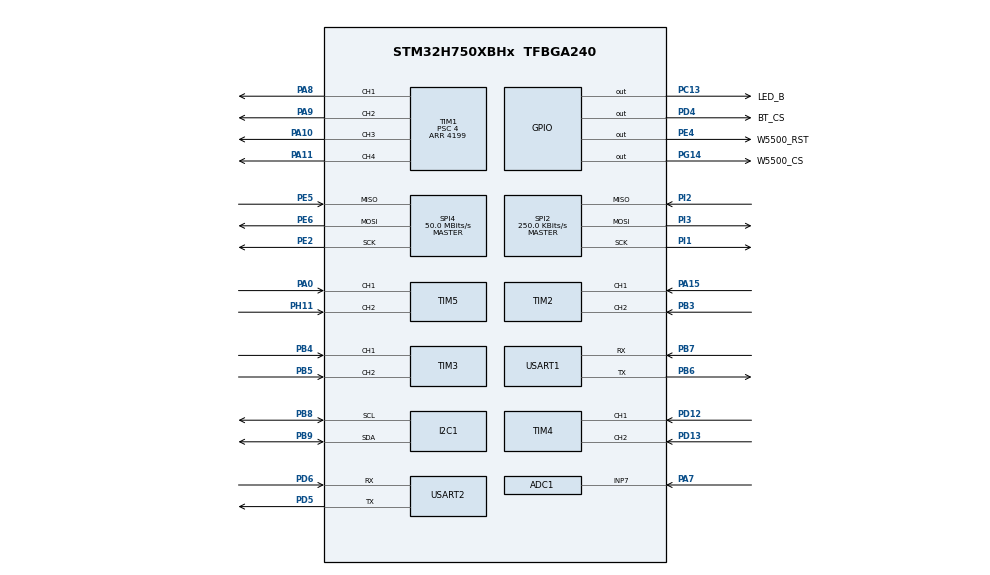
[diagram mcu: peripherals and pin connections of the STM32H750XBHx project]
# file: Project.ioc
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ADC1.Channel-0\#ChannelRegularConversion=ADC_CHANNEL_7
ADC1.NbrOfConversionFlag=1
ADC1.OffsetNumber-0\#ChannelRegularConversion=ADC_OFFSET_NONE
ADC1.OffsetSignedSaturation-0\#ChannelRegularConversion=DISABLE
ADC1.Rank-0\#ChannelRegularConversion=1
ADC1.SamplingTime-0\#ChannelRegularConversion=ADC_SAMPLETIME_1CYCLE_5
ADC1.master=1
CORTEX_M7.AccessPermission-Cortex_Memory_Protection_Unit_Region0_Settings=MPU_REGION_FULL_ACCESS
CORTEX_M7.AccessPermission-Cortex_Memory_Protection_Unit_Region1_Settings=MPU_REGION_FULL_ACCESS
CORTEX_M7.AccessPermission-Cortex_Memory_Protection_Unit_Region2_Settings=MPU_REGION_FULL_ACCESS
CORTEX_M7.AccessPermission-Cortex_Memory_Protection_Unit_Region3_Settings=MPU_REGION_FULL_ACCESS
CORTEX_M7.BaseAddress-Cortex_Memory_Protection_Unit_Region0_Settings=0x30000000
CORTEX_M7.BaseAddress-Cortex_Memory_Protection_Unit_Region1_Settings=0x40081000
CORTEX_M7.BaseAddress-Cortex_Memory_Protection_Unit_Region2_Settings=0x58020000
CORTEX_M7.BaseAddress-Cortex_Memory_Protection_Unit_Region3_Settings=0x40000000
CORTEX_M7.CPU_DCache=Enabled
CORTEX_M7.CPU_ICache=Enabled
CORTEX_M7.DisableExec-Cortex_Memory_Protection_Unit_Region0_Settings=MPU_INSTRUCTION_ACCESS_ENABLE
CORTEX_M7.DisableExec-Cortex_Memory_Protection_Unit_Region1_Settings=MPU_INSTRUCTION_ACCESS_ENABLE
CORTEX_M7.DisableExec-Cortex_Memory_Protection_Unit_Region2_Settings=MPU_INSTRUCTION_ACCESS_ENABLE
CORTEX_M7.DisableExec-Cortex_Memory_Protection_Unit_Region3_Settings=MPU_INSTRUCTION_ACCESS_ENABLE
CORTEX_M7.Enable-Cortex_Memory_Protection_Unit_Region0_Settings=MPU_REGION_ENABLE
CORTEX_M7.Enable-Cortex_Memory_Protection_Unit_Region1_Settings=MPU_REGION_ENABLE
CORTEX_M7.Enable-Cortex_Memory_Protection_Unit_Region2_Settings=MPU_REGION_ENABLE
CORTEX_M7.Enable-Cortex_Memory_Protection_Unit_Region3_Settings=MPU_REGION_ENABLE
CORTEX_M7.Enable-Cortex_Memory_Protection_Unit_Region4_Settings=__NULL
CORTEX_M7.IsBufferable-Cortex_Memory_Protection_Unit_Region0_Settings=MPU_ACCESS_NOT_BUFFERABLE
CORTEX_M7.MPU_Control=MPU_PRIVILEGED_DEFAULT
CORTEX_M7.Size-Cortex_Memory_Protection_Unit_Region0_Settings=MPU_REGION_SIZE_256KB
CORTEX_M7.Size-Cortex_Memory_Protection_Unit_Region1_Settings=MPU_REGION_SIZE_256KB
CORTEX_M7.Size-Cortex_Memory_Protection_Unit_Region2_Settings=MPU_REGION_SIZE_16KB
CORTEX_M7.Size-Cortex_Memory_Protection_Unit_Region3_Settings=MPU_REGION_SIZE_1MB
I2C1.Timing=0x10C0ECFF
Mcu.Family=STM32H7
Mcu.Name=STM32H750XBHx
Mcu.Package=TFBGA240
NVIC.PriorityGroup=NVIC_PRIORITYGROUP_4
NVIC.TIM6_DAC_IRQn=true\:15\:0\:false\:false\:true\:false\:true\:true
NVIC.TimeBase=TIM6_DAC_IRQn
NVIC.TimeBaseIP=TIM6
PA0.Signal=S_TIM5_CH1
PA10.Signal=S_TIM1_CH3
PA11.Signal=S_TIM1_CH4
PA15\ (JTDI).Signal=S_TIM2_CH1_ETR
PA7.Signal=ADCx_INP7
PA8.Signal=S_TIM1_CH1
PA9.Signal=S_TIM1_CH2
PB3\ (JTDO/TRACESWO).Signal=S_TIM2_CH2
PB4\ (NJTRST).Signal=S_TIM3_CH1
PB5.Signal=S_TIM3_CH2
PB6.Mode=Asynchronous
PB6.Signal=USART1_TX
PB7.Mode=Asynchronous
PB7.Signal=USART1_RX
PB8.Mode=I2C
PB8.Signal=I2C1_SCL
PB9.Mode=I2C
PB9.Signal=I2C1_SDA
PC13.GPIO_Label=LED_B
PC13.Signal=GPIO_Output
PD12.Signal=S_TIM4_CH1
PD13.Signal=S_TIM4_CH2
PD4.GPIO_Label=BT_CS
PD4.Signal=GPIO_Output
PD5.Mode=Asynchronous
PD5.Signal=USART2_TX
PD6.Mode=Asynchronous
PD6.Signal=USART2_RX
PE2.Mode=Full_Duplex_Master
PE2.Signal=SPI4_SCK
PE4.GPIO_Label=W5500_RST
PE4.Signal=GPIO_Output
PE5.Mode=Full_Duplex_Master
PE5.Signal=SPI4_MISO
PE6.Mode=Full_Duplex_Master
PE6.Signal=SPI4_MOSI
PG14.GPIO_Label=W5500_CS
PG14.Signal=GPIO_Output
PH0-OSC_IN\ (PH0).Mode=HSE-External-Oscillator
PH0-OSC_IN\ (PH0).Signal=RCC_OSC_IN
PH1-OSC_OUT\ (PH1).Mode=HSE-External-Oscillator
PH1-OSC_OUT\ (PH1).Signal=RCC_OSC_OUT
PH11.Signal=S_TIM5_CH2
PI1.Mode=Full_Duplex_Master
PI1.Signal=SPI2_SCK
PI2.Mode=Full_Duplex_Master
PI2.Signal=SPI2_MISO
PI3.Mode=Full_Duplex_Master
PI3.Signal=SPI2_MOSI
ProjectManager.HeapSize=0x1000
ProjectManager.StackSize=0x1000
ProjectManager.TargetToolchain=MDK-ARM V5.27
RCC.ADCCLockSelection=RCC_ADCCLKSOURCE_CLKP
RCC.ADCFreq_Value=64000000
RCC.APB1Freq_Value=100000000
RCC.APB2Freq_Value=100000000
RCC.APB3Freq_Value=100000000
RCC.APB4Freq_Value=100000000
RCC.CortexFreq_Value=400000000
RCC.D1PPRE=RCC_APB3_DIV2
RCC.D2PPRE1=RCC_APB1_DIV2
RCC.D2PPRE2=RCC_APB2_DIV2
RCC.D3PPRE=RCC_APB4_DIV2
RCC.DIVM1=5
RCC.DIVM2=5
RCC.DIVM3=5
RCC.DIVN1=160
RCC.DIVN2=192
RCC.DIVN3=192
RCC.HCLKFreq_Value=200000000
RCC.HPRE=RCC_HCLK_DIV2
RCC.PLLSourceVirtual=RCC_PLLSOURCE_HSE
RCC.SPI123CLockSelection=RCC_SPI123CLKSOURCE_CLKP
RCC.SYSCLKFreq_VALUE=400000000
RCC.SYSCLKSource=RCC_SYSCLKSOURCE_PLLCLK
RCC.Tim1Mul=2
RCC.USBFreq_Value=400000000
SH.ADCx_INP7.0=ADC1_INP7,IN7-Single-Ended
SH.S_TIM1_CH1.0=TIM1_CH1,PWM Generation1 CH1
SH.S_TIM1_CH2.0=TIM1_CH2,PWM Generation2 CH2
SH.S_TIM1_CH3.0=TIM1_CH3,PWM Generation3 CH3
SH.S_TIM1_CH4.0=TIM1_CH4,PWM Generation4 CH4
SH.S_TIM2_CH1_ETR.0=TIM2_CH1,Encoder_Interface
SH.S_TIM2_CH2.0=TIM2_CH2,Encoder_Interface
SH.S_TIM3_CH1.0=TIM3_CH1,Encoder_Interface
SH.S_TIM3_CH2.0=TIM3_CH2,Encoder_Interface
SH.S_TIM4_CH1.0=TIM4_CH1,Encoder_Interface
SH.S_TIM4_CH2.0=TIM4_CH2,Encoder_Interface
SH.S_TIM5_CH1.0=TIM5_CH1,Encoder_Interface
SH.S_TIM5_CH2.0=TIM5_CH2,Encoder_Interface
SPI2.BaudRatePrescaler=SPI_BAUDRATEPRESCALER_256
SPI2.CLKPhase=SPI_PHASE_2EDGE
SPI2.CLKPolarity=SPI_POLARITY_HIGH
SPI2.CalculateBaudRate=250.0 KBits/s
SPI2.DataSize=SPI_DATASIZE_8BIT
SPI2.Direction=SPI_DIRECTION_2LINES
SPI2.FirstBit=SPI_FIRSTBIT_LSB
SPI2.Mode=SPI_MODE_MASTER
SPI2.NSSPMode=SPI_NSS_PULSE_DISABLE
SPI2.VirtualType=VM_MASTER
SPI4.CalculateBaudRate=50.0 MBits/s
SPI4.DataSize=SPI_DATASIZE_8BIT
SPI4.Direction=SPI_DIRECTION_2LINES
SPI4.Mode=SPI_MODE_MASTER
SPI4.NSSPMode=SPI_NSS_PULSE_DISABLE
SPI4.VirtualType=VM_MASTER
TIM1.Channel-PWM\ Generation1\ CH1=TIM_CHANNEL_1
TIM1.Channel-PWM\ Generation2\ CH2=TIM_CHANNEL_2
TIM1.Channel-PWM\ Generation3\ CH3=TIM_CHANNEL_3
TIM1.Channel-PWM\ Generation4\ CH4=TIM_CHANNEL_4
TIM1.Period=4199
TIM1.Prescaler=4
USART1.VirtualMode-Asynchronous=VM_ASYNC
USART2.VirtualMode-Asynchronous=VM_ASYNC
VP_MEMORYMAP_VS_MEMORYMAP.Mode=CurAppReg
VP_SYS_VS_tim6.Mode=TIM6
VP_TIM1_VS_ClockSourceINT.Mode=Internal
board=custom

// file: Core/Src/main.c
/* USER CODE BEGIN Header */
/**
  ******************************************************************************
  * @file           : main.c
  * @brief          : Main program body
  ******************************************************************************
  * @attention
  *
  * <h2><center>&copy; Copyright (c) 2021 STMicroelectronics.
  * All rights reserved.</center></h2>
  *
  * This software component is licensed by ST under Ultimate Liberty license
  * SLA0044, the "License"; You may not use this file except in compliance with
  * the License. You may obtain a copy of the License at:
  *                             www.st.com/SLA0044
  *
  ******************************************************************************
  */
/* USER CODE END Header */
#include "main.h"
#include "adc.h"
#include "i2c.h"
#include "memorymap.h"
#include "spi.h"
#include "tim.h"
#include "usart.h"
#include "gpio.h"

/* USER CODE BEGIN Includes */
#include <stdio.h>
#include "adc.h"
#include "lcd_spi_200.h"
#include "servo.h"
#include "robot.h"

extern void freertos_start(void);

/* USER CODE END Includes */

void SystemClock_Config(void);
void PeriphCommonClock_Config(void);
static void MPU_Config(void);

int main(void)
{

  /* MPU Configuration--------------------------------------------------------*/
  MPU_Config();

  /* Enable the CPU Cache */

  /* Enable I-Cache---------------------------------------------------------*/
  SCB_EnableICache();

  /* Enable D-Cache---------------------------------------------------------*/
  SCB_EnableDCache();

  /* MCU Configuration--------------------------------------------------------*/

  /* Reset of all peripherals, Initializes the Flash interface and the Systick. */
  HAL_Init();

  /* Configure the system clock */
  SystemClock_Config();

  /* Configure the peripherals common clocks */
  PeriphCommonClock_Config();

  /* Initialize all configured peripherals */
  MX_GPIO_Init();
  MX_USART1_UART_Init();
  MX_SPI4_Init();
  MX_SPI2_Init();
  MX_TIM1_Init();
  MX_TIM2_Init();
  MX_TIM3_Init();
  MX_TIM4_Init();
  MX_TIM5_Init();
  MX_USART2_UART_Init();
  MX_I2C1_Init();
  MX_ADC1_Init();
  /* USER CODE BEGIN 2 */
  MX_GPIO_UserInit();
  SPI_LCD_Init();
  Servo_Init();
  Robot_Init();
  /* FreeRTOS 调度器（不再返回） */
    freertos_start();
  /* USER CODE END 2 */

  /* Infinite loop */
  while (1)
  {

  }
}

void SystemClock_Config(void)
{
  RCC_OscInitTypeDef RCC_OscInitStruct = {0};
  RCC_ClkInitTypeDef RCC_ClkInitStruct = {0};

  /** Supply configuration update enable
  */
  HAL_PWREx_ConfigSupply(PWR_LDO_SUPPLY);

  /** Configure the main internal regulator output voltage
  */
  __HAL_PWR_VOLTAGESCALING_CONFIG(PWR_REGULATOR_VOLTAGE_SCALE1);

  while(!__HAL_PWR_GET_FLAG(PWR_FLAG_VOSRDY)) {}

  /** Initializes the RCC Oscillators according to the specified parameters
  * in the RCC_OscInitTypeDef structure.
  */
  RCC_OscInitStruct.OscillatorType = RCC_OSCILLATORTYPE_HSI|RCC_OSCILLATORTYPE_HSE;
  RCC_OscInitStruct.HSEState = RCC_HSE_ON;
  RCC_OscInitStruct.HSIState = RCC_HSI_DIV1;
  RCC_OscInitStruct.HSICalibrationValue = RCC_HSICALIBRATION_DEFAULT;
  RCC_OscInitStruct.PLL.PLLState = RCC_PLL_ON;
  RCC_OscInitStruct.PLL.PLLSource = RCC_PLLSOURCE_HSE;
  RCC_OscInitStruct.PLL.PLLM = 5;
  RCC_OscInitStruct.PLL.PLLN = 160;
  RCC_OscInitStruct.PLL.PLLP = 2;
  RCC_OscInitStruct.PLL.PLLQ = 2;
  RCC_OscInitStruct.PLL.PLLR = 2;
  RCC_OscInitStruct.PLL.PLLRGE = RCC_PLL1VCIRANGE_2;
  RCC_OscInitStruct.PLL.PLLVCOSEL = RCC_PLL1VCOWIDE;
  RCC_OscInitStruct.PLL.PLLFRACN = 0;
  if (HAL_RCC_OscConfig(&RCC_OscInitStruct) != HAL_OK)
  {
    Error_Handler();
  }

  /** Initializes the CPU, AHB and APB buses clocks
  */
  RCC_ClkInitStruct.ClockType = RCC_CLOCKTYPE_HCLK|RCC_CLOCKTYPE_SYSCLK
                              |RCC_CLOCKTYPE_PCLK1|RCC_CLOCKTYPE_PCLK2
                              |RCC_CLOCKTYPE_D3PCLK1|RCC_CLOCKTYPE_D1PCLK1;
  RCC_ClkInitStruct.SYSCLKSource = RCC_SYSCLKSOURCE_PLLCLK;
  RCC_ClkInitStruct.SYSCLKDivider = RCC_SYSCLK_DIV1;
  RCC_ClkInitStruct.AHBCLKDivider = RCC_HCLK_DIV2;
  RCC_ClkInitStruct.APB3CLKDivider = RCC_APB3_DIV2;
  RCC_ClkInitStruct.APB1CLKDivider = RCC_APB1_DIV2;
  RCC_ClkInitStruct.APB2CLKDivider = RCC_APB2_DIV2;
  RCC_ClkInitStruct.APB4CLKDivider = RCC_APB4_DIV2;

  if (HAL_RCC_ClockConfig(&RCC_ClkInitStruct, FLASH_LATENCY_2) != HAL_OK)
  {
    Error_Handler();
  }
}

void PeriphCommonClock_Config(void)
{
  RCC_PeriphCLKInitTypeDef PeriphClkInitStruct = {0};

  /** Initializes the peripherals clock
  */
  PeriphClkInitStruct.PeriphClockSelection = RCC_PERIPHCLK_CKPER;
  PeriphClkInitStruct.CkperClockSelection = RCC_CLKPSOURCE_HSI;
  if (HAL_RCCEx_PeriphCLKConfig(&PeriphClkInitStruct) != HAL_OK)
  {
    Error_Handler();
  }
}

 /* MPU Configuration */

void MPU_Config(void)
{
  MPU_Region_InitTypeDef MPU_InitStruct = {0};

  /* Disables the MPU */
  HAL_MPU_Disable();

  /** Initializes and configures the Region and the memory to be protected
  */
  MPU_InitStruct.Enable = MPU_REGION_ENABLE;
  MPU_InitStruct.Number = MPU_REGION_NUMBER0;
  MPU_InitStruct.BaseAddress = 0x30000000;
  MPU_InitStruct.Size = MPU_REGION_SIZE_256KB;
  MPU_InitStruct.SubRegionDisable = 0x0;
  MPU_InitStruct.TypeExtField = MPU_TEX_LEVEL0;
  MPU_InitStruct.AccessPermission = MPU_REGION_FULL_ACCESS;
  MPU_InitStruct.DisableExec = MPU_INSTRUCTION_ACCESS_ENABLE;
  MPU_InitStruct.IsShareable = MPU_ACCESS_NOT_SHAREABLE;
  MPU_InitStruct.IsCacheable = MPU_ACCESS_NOT_CACHEABLE;
  MPU_InitStruct.IsBufferable = MPU_ACCESS_NOT_BUFFERABLE;

  HAL_MPU_ConfigRegion(&MPU_InitStruct);

  /** Initializes and configures the Region and the memory to be protected
  */
  MPU_InitStruct.Number = MPU_REGION_NUMBER1;
  MPU_InitStruct.BaseAddress = 0x40081000;

  HAL_MPU_ConfigRegion(&MPU_InitStruct);

  /** Initializes and configures the Region and the memory to be protected
  */
  MPU_InitStruct.Number = MPU_REGION_NUMBER2;
  MPU_InitStruct.BaseAddress = 0x58020000;
  MPU_InitStruct.Size = MPU_REGION_SIZE_16KB;

  HAL_MPU_ConfigRegion(&MPU_InitStruct);

  /** Initializes and configures the Region and the memory to be protected
  */
  MPU_InitStruct.Number = MPU_REGION_NUMBER3;
  MPU_InitStruct.BaseAddress = 0x40000000;
  MPU_InitStruct.Size = MPU_REGION_SIZE_1MB;

  HAL_MPU_ConfigRegion(&MPU_InitStruct);
  /* Enables the MPU */
  HAL_MPU_Enable(MPU_PRIVILEGED_DEFAULT);

}

void HAL_TIM_PeriodElapsedCallback(TIM_HandleTypeDef *htim)
{
  if (htim->Instance == TIM6)
  {
    HAL_IncTick();
  }
}

void Error_Handler(void)
{
  __disable_irq();
  while (1)
  {
  }
}
